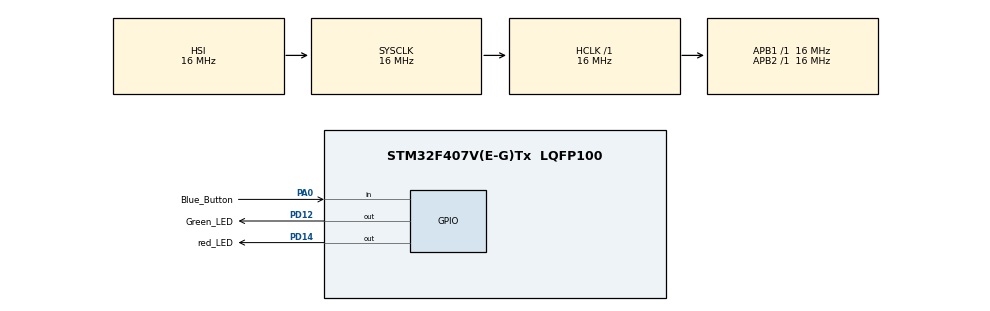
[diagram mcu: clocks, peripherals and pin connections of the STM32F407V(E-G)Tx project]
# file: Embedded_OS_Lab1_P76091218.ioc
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Mcu.Family=STM32F4
PD12.GPIO_Label=Green_LED
VP_SYS_VS_tim6.Mode=TIM6
RCC.CortexFreq_Value=16000000
NVIC.TIM6_DAC_IRQn=true\:0\:0\:false\:false\:true\:false\:true
ProjectManager.StackSize=0x400
PA0-WKUP.GPIO_Label=Blue_Button
PA0-WKUP.Signal=GPIO_Input
PA13.Signal=SYS_JTMS-SWDIO
ProjectManager.TargetToolchain=STM32CubeIDE
RCC.LSE_VALUE=32768
RCC.AHBFreq_Value=16000000
RCC.HSE_VALUE=25000000
board=custom
RCC.VCOOutputFreq_Value=192000000
RCC.APB2Freq_Value=16000000
PA14.Mode=Serial_Wire
PD14.GPIO_Label=red_LED
PA13.Mode=Serial_Wire
Mcu.Name=STM32F407V(E-G)Tx
PD14.Signal=GPIO_Output
RCC.SYSCLKFreq_VALUE=16000000
Mcu.Package=LQFP100
NVIC.TimeBase=TIM6_DAC_IRQn
PD12.Signal=GPIO_Output
NVIC.TimeBaseIP=TIM6
PA14.Signal=SYS_JTCK-SWCLK
ProjectManager.HeapSize=0x200
RCC.HSI_VALUE=16000000
NVIC.PriorityGroup=NVIC_PRIORITYGROUP_4
RCC.APB1Freq_Value=16000000

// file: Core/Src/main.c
/* USER CODE BEGIN Header */
/**
  ******************************************************************************
  * @file           : main.c
  * @brief          : Main program body
  ******************************************************************************
  * @attention
  *
  * <h2><center>&copy; Copyright (c) 2021 STMicroelectronics.
  * All rights reserved.</center></h2>
  *
  * This software component is licensed by ST under BSD 3-Clause license,
  * the "License"; You may not use this file except in compliance with the
  * License. You may obtain a copy of the License at:
  *                        opensource.org/licenses/BSD-3-Clause
  *
  ******************************************************************************
  */
/* USER CODE END Header */
#include "main.h"
#include "FreeRTOS.h"
#include "task.h"
#include "queue.h"

void SystemClock_Config(void);
static void MX_GPIO_Init(void);
//void vTaskCode(void);
void vLedHandler(void);
void vButtonHandler(void);
//void vTaskCode2(void);

/* USER CODE BEGIN 0 */
QueueHandle_t xQueue;
//bool now;
/* USER CODE END 0 */

int main(void)
{

  /* MCU Configuration--------------------------------------------------------*/

  /* Reset of all peripherals, Initializes the Flash interface and the Systick. */
  HAL_Init();

  /* Configure the system clock */
  SystemClock_Config();

  /* Initialize all configured peripherals */
  MX_GPIO_Init();
  /* USER CODE BEGIN 2 */
  //xTaskCreate(
	//	  vTaskCode,  /* Function that implements the task. */
	//	  "NAME",          /* Text name for the task. */
	//	  128,      /* Stack size in words, not bytes. */
	//	  NULL,   /* Parameter passed into the task. */
	//	  0,/* Priority at which the task is created. */
	//	  NULL
	//	  );
  //xQueue1 = xQueueCreate( 10, sizeof(int) );

    xQueue = xQueueCreate(10, sizeof(int));

    BaseType_t xledtask = xTaskCreate(vLedHandler,
                                        "LED",
                                        128,
                                        xQueue,
                                        1,
                                        NULL);

    BaseType_t xbuttontask = xTaskCreate(vButtonHandler,
                                        "BUTTON",
                                        128,
                                        xQueue,
                                        1,
                                        NULL);
  vTaskStartScheduler();
  /* USER CODE END 2 */

  /* Infinite loop */
  while (1)
  {

  }
}

void SystemClock_Config(void)
{
  RCC_OscInitTypeDef RCC_OscInitStruct = {0};
  RCC_ClkInitTypeDef RCC_ClkInitStruct = {0};

  /** Configure the main internal regulator output voltage
  */
  __HAL_RCC_PWR_CLK_ENABLE();
  __HAL_PWR_VOLTAGESCALING_CONFIG(PWR_REGULATOR_VOLTAGE_SCALE1);
  /** Initializes the RCC Oscillators according to the specified parameters
  * in the RCC_OscInitTypeDef structure.
  */
  RCC_OscInitStruct.OscillatorType = RCC_OSCILLATORTYPE_HSI;
  RCC_OscInitStruct.HSIState = RCC_HSI_ON;
  RCC_OscInitStruct.HSICalibrationValue = RCC_HSICALIBRATION_DEFAULT;
  RCC_OscInitStruct.PLL.PLLState = RCC_PLL_NONE;
  if (HAL_RCC_OscConfig(&RCC_OscInitStruct) != HAL_OK)
  {
    Error_Handler();
  }
  /** Initializes the CPU, AHB and APB buses clocks
  */
  RCC_ClkInitStruct.ClockType = RCC_CLOCKTYPE_HCLK|RCC_CLOCKTYPE_SYSCLK
                              |RCC_CLOCKTYPE_PCLK1|RCC_CLOCKTYPE_PCLK2;
  RCC_ClkInitStruct.SYSCLKSource = RCC_SYSCLKSOURCE_HSI;
  RCC_ClkInitStruct.AHBCLKDivider = RCC_SYSCLK_DIV1;
  RCC_ClkInitStruct.APB1CLKDivider = RCC_HCLK_DIV1;
  RCC_ClkInitStruct.APB2CLKDivider = RCC_HCLK_DIV1;

  if (HAL_RCC_ClockConfig(&RCC_ClkInitStruct, FLASH_LATENCY_0) != HAL_OK)
  {
    Error_Handler();
  }
}

static void MX_GPIO_Init(void)
{
  GPIO_InitTypeDef GPIO_InitStruct = {0};

  /* GPIO Ports Clock Enable */
  __HAL_RCC_GPIOA_CLK_ENABLE();
  __HAL_RCC_GPIOD_CLK_ENABLE();

  /*Configure GPIO pin Output Level */
  HAL_GPIO_WritePin(GPIOD, Green_LED_Pin|red_LED_Pin, GPIO_PIN_RESET);

  /*Configure GPIO pin : Blue_Button_Pin */
  GPIO_InitStruct.Pin = Blue_Button_Pin;
  GPIO_InitStruct.Mode = GPIO_MODE_INPUT;
  GPIO_InitStruct.Pull = GPIO_NOPULL;
  HAL_GPIO_Init(Blue_Button_GPIO_Port, &GPIO_InitStruct);

  /*Configure GPIO pins : Green_LED_Pin red_LED_Pin */
  GPIO_InitStruct.Pin = Green_LED_Pin|red_LED_Pin;
  GPIO_InitStruct.Mode = GPIO_MODE_OUTPUT_PP;
  GPIO_InitStruct.Pull = GPIO_NOPULL;
  GPIO_InitStruct.Speed = GPIO_SPEED_FREQ_LOW;
  HAL_GPIO_Init(GPIOD, &GPIO_InitStruct);

}

/* USER CODE BEGIN 4 */

void vLedHandler()
  {
	  int databuffer = 0;
	  int mode = 0;//控制模式

    for( ;; ){
      //mode 0 green&red交替亮
      if(mode == 0){
        HAL_GPIO_WritePin(Green_LED_GPIO_Port,GPIO_PIN_12,1);
        if(xQueueReceive(xQueue,&databuffer,5000)){
          //vTaskDelay(5000);
          mode = (mode+1)%2;
          HAL_GPIO_WritePin(Green_LED_GPIO_Port,GPIO_PIN_12,0);////////
          continue;
        }
        //vTaskDelay(5000);
        HAL_GPIO_WritePin(Green_LED_GPIO_Port,GPIO_PIN_12,0);
        if(xQueueReceive(xQueue,&databuffer,0)){
          //vTaskDelay(5000);
          mode = (mode+1)%2;
          continue;
        }
        HAL_GPIO_WritePin(red_LED_GPIO_Port,GPIO_PIN_14,1);
        if(xQueueReceive(xQueue,&databuffer,5000)){
          //vTaskDelay(5000);
          mode = (mode+1)%2;
          HAL_GPIO_WritePin(red_LED_GPIO_Port,GPIO_PIN_14,0);/////////
          continue;
        }
        HAL_GPIO_WritePin(red_LED_GPIO_Port,GPIO_PIN_14,0);
        if(xQueueReceive(xQueue,&databuffer,0)){
          //vTaskDelay(5000);
          mode = (mode+1)%2;
          continue;
        }
      }
      //mode 1 green&red交替亮
      else if(mode == 1){
        HAL_GPIO_WritePin(red_LED_GPIO_Port,GPIO_PIN_14,1);
        if(xQueueReceive(xQueue,&databuffer,500)){
          //vTaskDelay(1000);
          mode = (mode+1)%2;
          HAL_GPIO_WritePin(red_LED_GPIO_Port,GPIO_PIN_14,0);/////////
          continue;
        }
        HAL_GPIO_WritePin(red_LED_GPIO_Port,GPIO_PIN_14,0);
        if(xQueueReceive(xQueue,&databuffer,500)){
          //vTaskDelay(1000);
          mode = (mode+1)%2;
          continue;
        }
      }

    }
  }

void vButtonHandler(){
	bool item = 1; //丟個標記讓queue知道要接收東西
  GPIO_PinState now = 0;
  GPIO_PinState pre = 0;
	for( ;; )
	{
    now = HAL_GPIO_ReadPin(Blue_Button_GPIO_Port,GPIO_PIN_0);
    if(now != pre){
      if(now == 1){
        pre = 1;
        xQueueSend(xQueue,&item,0);
      }
      else if(now == 0){
      pre = 0;
      }
    }

	vTaskDelay(300);
	}
}

/* USER CODE END 4 */

 /**
  * @brief  Period elapsed callback in non blocking mode
  * @note   This function is called  when TIM6 interrupt took place, inside
  * HAL_TIM_IRQHandler(). It makes a direct call to HAL_IncTick() to increment
  * a global variable "uwTick" used as application time base.
  * @param  htim : TIM handle
  * @retval None
  */
void HAL_TIM_PeriodElapsedCallback(TIM_HandleTypeDef *htim)
{
  if (htim->Instance == TIM6) {
    HAL_IncTick();
  }
}

void Error_Handler(void)
{
  __disable_irq();
  while (1)
  {
  }
}

/************************ (C) COPYRIGHT STMicroelectronics *****END OF FILE****/
